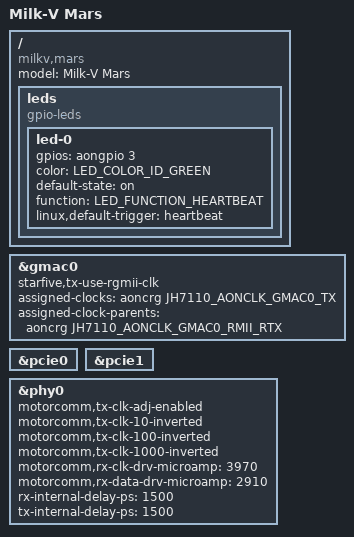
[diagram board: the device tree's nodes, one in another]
// SPDX-License-Identifier: GPL-2.0 OR MIT
/*
 * Copyright (C) 2023 Jisheng Zhang <jszhang@kernel.org>
 */

/dts-v1/;
#include <dt-bindings/gpio/gpio.h>
#include <dt-bindings/leds/common.h>
#include "jh7110-common.dtsi"

/ {
	model = "Milk-V Mars";
	compatible = "milkv,mars", "starfive,jh7110";

	leds {
		compatible = "gpio-leds";

		led-0 {
			gpios = <&aongpio 3 GPIO_ACTIVE_HIGH>;
			color = <LED_COLOR_ID_GREEN>;
			default-state = "on";
			function = LED_FUNCTION_HEARTBEAT;
			linux,default-trigger = "heartbeat";
		};
	};
};

&gmac0 {
	starfive,tx-use-rgmii-clk;
	assigned-clocks = <&aoncrg JH7110_AONCLK_GMAC0_TX>;
	assigned-clock-parents = <&aoncrg JH7110_AONCLK_GMAC0_RMII_RTX>;
};

&pcie0 {
	status = "okay";
};

&pcie1 {
	status = "okay";
};

&phy0 {
	motorcomm,tx-clk-adj-enabled;
	motorcomm,tx-clk-10-inverted;
	motorcomm,tx-clk-100-inverted;
	motorcomm,tx-clk-1000-inverted;
	motorcomm,rx-clk-drv-microamp = <3970>;
	motorcomm,rx-data-drv-microamp = <2910>;
	rx-internal-delay-ps = <1500>;
	tx-internal-delay-ps = <1500>;
};
